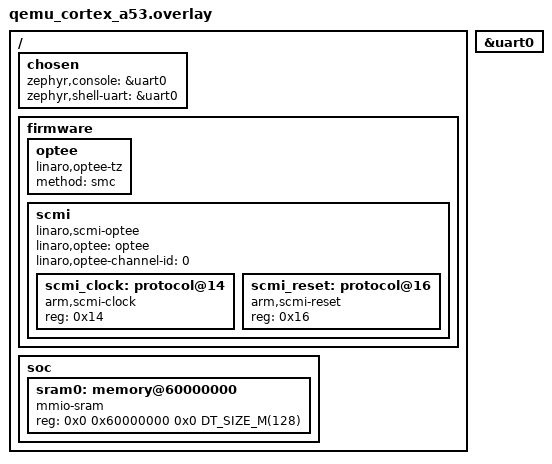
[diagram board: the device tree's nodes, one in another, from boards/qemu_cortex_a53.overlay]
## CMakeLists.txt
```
# SPDX-License-Identifier: Apache-2.0

cmake_minimum_required(VERSION 3.28.0)

find_package(Zephyr REQUIRED HINTS $ENV{ZEPHYR_BASE})
project(scmi)

target_sources(app PRIVATE src/main.c)
```

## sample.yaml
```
sample:
  name: scmi
  description: This sample demonstrates the interaction between an agent
    running Zephyr and the platform via SCMI.
tests:
  sample.drivers.firmware.scmi:
    build_only: true
    filter: CONFIG_ARM_SCMI
    integration_platforms:
      - imx95_evk/mimx9596/m7
      - imx95_evk/mimx9596/a55
```

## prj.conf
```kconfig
CONFIG_ARM_SCMI_SHELL=y
CONFIG_BOOT_BANNER=n
CONFIG_ARM_SCMI_BASE_HELPERS=y
```

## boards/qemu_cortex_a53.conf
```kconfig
# Copyright (c) 2026 EPAM Systems
# SPDX-License-Identifier: Apache-2.0

CONFIG_LOG=y
CONFIG_LOG_MODE_MINIMAL=y
CONFIG_PRINTK=y
CONFIG_SHELL=y

CONFIG_EARLY_CONSOLE=y
CONFIG_ARM_SCMI=y
CONFIG_CLOCK_CONTROL=y

# Boot in Non-Secure world for OP-TEE interaction
CONFIG_ARMV8_A_NS=y

CONFIG_HEAP_MEM_POOL_SIZE=65536

CONFIG_RESET=y
```

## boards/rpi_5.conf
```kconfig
# Copyright (c) 2026 EPAM Systems
# SPDX-License-Identifier: Apache-2.0

CONFIG_LOG=y
CONFIG_LOG_MODE_MINIMAL=y
CONFIG_PRINTK=y
CONFIG_SHELL=y

CONFIG_EARLY_CONSOLE=y

CONFIG_CLOCK_CONTROL=y

CONFIG_ARM_SCMI=y

CONFIG_RESET=y
```

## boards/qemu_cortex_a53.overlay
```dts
/*
 * Copyright (c) 2026 EPAM Systems
 *
 * SPDX-License-Identifier: Apache-2.0
 */

/ {
	chosen {
		zephyr,console = &uart0;
		zephyr,shell-uart = &uart0;
	};

	firmware {
		optee: optee {
			compatible = "linaro,optee-tz";
			method = "smc";
			status = "okay";
		};

		scmi {
			compatible = "linaro,scmi-optee";
			#address-cells = <1>;
			#size-cells = <0>;
			linaro,optee = <&optee>;
			linaro,optee-channel-id = <0>;

			scmi_clock: protocol@14 {
				compatible = "arm,scmi-clock";
				reg = <0x14>;
				#clock-cells = <1>;
			};

			scmi_reset: protocol@16 {
				compatible = "arm,scmi-reset";
				reg = <0x16>;
				#reset-cells = <1>;
			};
		};
	};

	soc {
		/delete-node/ memory@40000000;

		sram0: memory@60000000 {
			compatible = "mmio-sram";
			reg = <0x0 0x60000000 0x0 DT_SIZE_M(128)>;
		};
	};
};

&uart0 {
	status = "okay";
};
```

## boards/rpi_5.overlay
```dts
/*
 * Copyright (c) 2026 EPAM Systems
 *
 * SPDX-License-Identifier: Apache-2.0
 */

/ {
	firmware {
		scmi {
			compatible = "arm,scmi-smc";
			shmem = <&scmi_buf>;
			#address-cells = <1>;
			#size-cells = <0>;
			arm,smc-id = <0x82000002>;

			scmi_reset: protocol@16 {
				compatible = "arm,scmi-reset";
				reg = <0x16>;
				#reset-cells = <1>;
				status = "okay";
			};
		};
	};

	reserved-memory {
		ranges;
		#address-cells = <2>;
		#size-cells = <1>;

		scmi_buf: scmi@3ff00000 {
			compatible = "arm,scmi-shmem";
			reg = <0x0 0x3ff00000 0x1000>;
		};
	};
};
```

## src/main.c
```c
/*
 * Copyright 2026 NXP
 *
 * SPDX-License-Identifier: Apache-2.0
 */

int main(void)
{
	return 0;
}
```
